# STM32U3B5 register map
File version: 1.0
CPU: CM33 r0p1, little endian, MPU, FPU, 4 interrupt priority bits
Registers are 32-bit, read-write, reset 0x0 unless marked. A register's access mark holds for its fields unless they carry their own. Offsets are from the block's base; [hi:lo] are bit positions.

## ADC12 — ADC12 address block description
Base 0x42028300
Same registers: SEC_ADC12 0x52028300
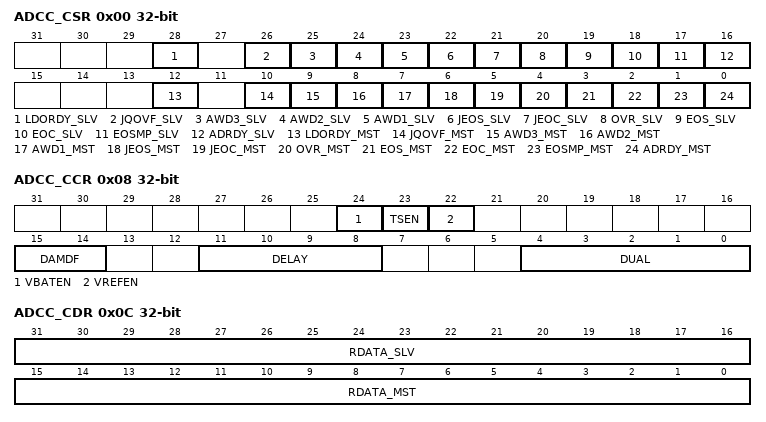
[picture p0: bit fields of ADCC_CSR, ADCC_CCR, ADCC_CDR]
0x00 ADCC_CSR ro — ADC common status register
  [28] LDORDY_SLV — ADC internal voltage regulator flag of the slave ADC
  [26] JQOVF_SLV — Injected context queue overflow flag of the slave ADC
  [25] AWD3_SLV — Analog watchdog 3 flag of the slave ADC
  [24] AWD2_SLV — Analog watchdog 2 flag of the slave ADC
  [23] AWD1_SLV — Analog watchdog 1 flag of the slave ADC
  [22] JEOS_SLV — End of injected sequence flag of the slave ADC
  [21] JEOC_SLV — End of injected conversion flag of the slave ADC
  [20] OVR_SLV — Overrun flag of the slave ADC
  [19] EOS_SLV — End of regular sequence flag of the slave ADC.
  [18] EOC_SLV — End of regular conversion of the slave ADC
  [17] EOSMP_SLV — End of sampling phase flag of the slave ADC
  [16] ADRDY_SLV — Slave ADC ready
  [12] LDORDY_MST — ADC internal voltage regulator flag of the master ADC
  [10] JQOVF_MST — Injected context queue overflow flag of the master ADC
  [9] AWD3_MST — Analog watchdog 3 flag of the master ADC
  [8] AWD2_MST — Analog watchdog 2 flag of the master ADC
  [7] AWD1_MST — Analog watchdog 1 flag of the master ADC
  [6] JEOS_MST — End of injected sequence flag of the master ADC
  [5] JEOC_MST — End of injected conversion flag of the master ADC
  [4] OVR_MST — Overrun flag of the master ADC
  [3] EOS_MST — End of regular sequence flag of the master ADC
  [2] EOC_MST — End of regular conversion of the master ADC
  [1] EOSMP_MST — End of Sampling phase flag of the master ADC
  [0] ADRDY_MST — Master ADC ready
0x08 ADCC_CCR — ADC common control register
  [24] VBATEN — VBAT enable
    0=Vless thansub>BATless than/sub> channel disabled; 1=Vless thansub>BATless than/sub> channel enabled
  [23] TSEN — Temperature sensor voltage enable
    0=Temperature sensor channel disabled; 1=Temperature sensor channel enabled
  [22] VREFEN — Vless thansub>REFINTless than/sub> enable
    0=Vless thansub>REFINTless than/sub> channel disabled; 1=Vless thansub>REFINTless than/sub> channel enabled
  [15:14] DAMDF — Dual ADC mode data format
    0=Dual ADC mode without data packing (ADCC_CDR and ADCC_CDR2 registers not used); 2=Data formatting mode for any data width (ADCC_CDR data register is used when the data width is less than 16 bits, otherwise ADCC_CDR2 register is used); 3=Data formatting mode for data width lower that 8 bits (ADCC_CDR data register is used)
  [11:8] DELAY — Delay between two sampling phases
  [4:0] DUAL — Dual ADC mode selection
    0=Independent mode; 1=Combined regular simultaneous + Injected simultaneous mode; 2=Combined regular simultaneous + Alternate trigger mode; 3=Combined interleaved mode + Injected simultaneous mode; 5=Injected simultaneous mode only; 6=Regular simultaneous mode only; 7=Interleaved mode only; 9=Alternate trigger mode only
0x0C ADCC_CDR ro — ADC common regular data register for dual mode
  [31:16] RDATA_SLV — Regular data of the slave ADC
  [15:0] RDATA_MST — Regular data of the master ADC.
0x10 ADCC_CDR2 ro — ADC common regular data register for dual mode
  [31:0] RDATA_ALT — Regular data of the master/slave alternated ADCs.

## CRC — CRC address block description
Base 0x40023000
Same registers: SEC_CRC 0x50023000
0x00 CRC_DR reset 0xFFFFFFFF — CRC data register
  [31:0] DR — Data register bits
0x04 CRC_IDR — CRC independent data register
  [31:0] IDR — General-purpose 32-bit data register bits
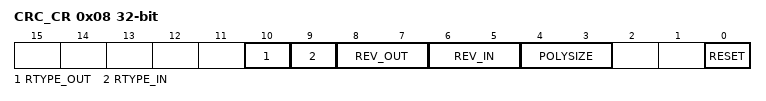
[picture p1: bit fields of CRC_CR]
0x08 CRC_CR — CRC control register
  [10] RTYPE_OUT — Reverse type output
    0=Bit level output; 1=Byte or half-word level output
  [9] RTYPE_IN — Reverse type input
    0=Bit level input; 1=Byte or half-word level input
  [8:7] REV_OUT — Reverse output data
    0=Bit order not affected (RTYPE_OUT=0 or 1); 1=Bit-reversed output format (RTYPE_OUT=0) or half-word reversal done by word (RTYPE_OUT=1); 2=Bit order not affected (RTYPE_OUT=0) or byte reversal done by word (RTYPE_OUT=1); 3=Bit order not affected (RTYPE_OUT=0 or 1)
  [6:5] REV_IN — Reverse input data
    0=Bit order not affected (RTYPE_IN=0 or 1); 1=Bit reversal done by byte (RTYPE_IN=0) or half-word reversal done by word (RTYPE_IN=1); 2=Bit reversal done by half-word (RTYPE_IN=0) or byte reversal done by word (RTYPE_IN=1); 3=Bit reversal done by word (RTYPE_IN=0) or bit order is not affected (RTYPE_IN=1)
  [4:3] POLYSIZE — Polynomial size
    0=32 bit polynomial; 1=16 bit polynomial; 2=8 bit polynomial; 3=7 bit polynomial
  [0] RESET — RESET bit
0x10 CRC_INIT reset 0xFFFFFFFF — CRC initial value
  [31:0] CRC_INIT — Programmable initial CRC value
0x14 CRC_POL reset 0x4C11DB7 — CRC polynomial
  [31:0] POL — Programmable polynomial

## Notices in the file
Copyright (c) 2025 STMicroelectronics.
SPDx-License-Identifier: Apache-2.0
Licensed under the Apache License, Version 2.0 (the "License");
you may not use this file except in compliance with the License.
You may obtain a copy of the License at
http://www.apache.org/licenses/LICENSE-2.0
Unless required by applicable law or agreed to in writing, software
distributed under the License is distributed on an "AS IS" BASIS,
WITHOUT WARRANTIES OR CONDITIONS OF ANY KIND, either express or implied.
See the License for the specific language governing permissions and
limitations under the License.
